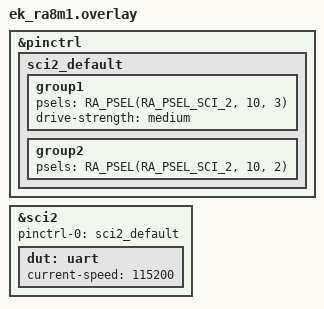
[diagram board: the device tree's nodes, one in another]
/*
 * Copyright (c) 2024 Renesas Electronics Corporation
 * SPDX-License-Identifier: Apache-2.0
 */

&pinctrl {
	sci2_default: sci2_default {
		group1 {
			/* tx */
			psels = <RA_PSEL(RA_PSEL_SCI_2, 10, 3)>;
			drive-strength = "medium";
		};
		group2 {
			/* rx */
			psels = <RA_PSEL(RA_PSEL_SCI_2, 10, 2)>;
		};
	};
};

&sci2 {
	pinctrl-0 = <&sci2_default>;
	pinctrl-names = "default";
	status = "okay";
	dut: uart {
		current-speed = <115200>;
		status = "okay";
	};
};
